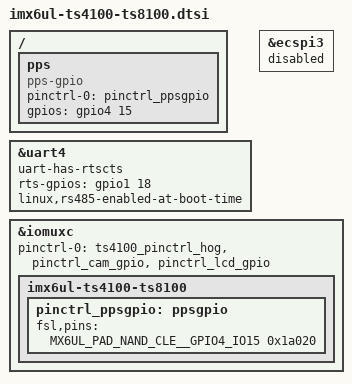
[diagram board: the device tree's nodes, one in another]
// SPDX-License-Identifier: GPL-2.0 OR X11
/*
 * Copyright (C) 2023 Technologic Systems, Inc. dba embeddedTS
 */

#include <dt-bindings/input/input.h>
/ {
	pps {
		compatible = "pps-gpio";
		pinctrl-names = "default";
		pinctrl-0 = <&pinctrl_ppsgpio>;
		gpios = <&gpio4 15 GPIO_ACTIVE_HIGH>;

		status = "okay";
	};
};

/* TODO: Due to the shared MDIO bus, its tricky to disable one eth MAC without
 * taking both of them out. Need to come back to this in the future.
&fec1 {
	status = "disabled";
};
*/

&uart4 {
	uart-has-rtscts;
	/* gpio 1_18 is initialized by the hog group in 4100.dtsi
	 * It is the SPARE_1 pin, needs to be set up in FPGA to pass to TXEN
	 * with the command 'tshwctl --out 0x33 --in 0x1'
	 */
	rts-gpios = <&gpio1 18 GPIO_ACTIVE_HIGH>;
	dma-names = "", "";
	linux,rs485-enabled-at-boot-time;
};

&ecspi3 {
        status = "disabled";
};

&iomuxc {
	pinctrl-names = "default";
	pinctrl-0 = <&ts4100_pinctrl_hog &pinctrl_cam_gpio &pinctrl_lcd_gpio>;

	imx6ul-ts4100-ts8100 {
		pinctrl_ppsgpio: ppsgpio {
			fsl,pins = <
				/* Normally ECSPI3 MISO */
				MX6UL_PAD_NAND_CLE__GPIO4_IO15	0x1a020
			>;
		};
	};
};
